AUTOSAR XML (schema 00048)
package /ComponentTypes
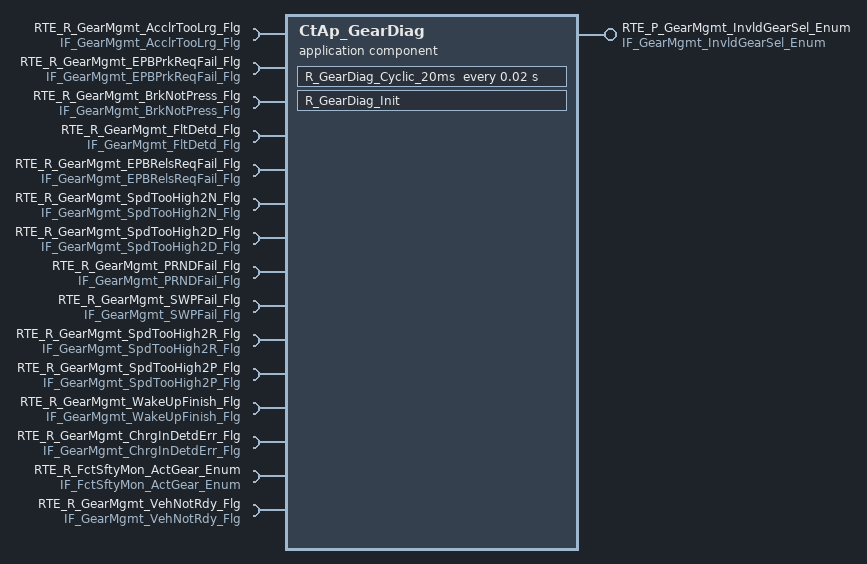
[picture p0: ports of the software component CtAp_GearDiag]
  application sw component type CtAp_GearDiag
    12 x require port:
      RTE_R_GearMgmt_AcclrTooLrg_Flg: nonqueued-receiver-com-spec{data-element=tec_GearMgmt_AcclrTooLrg_Flg, filter=data-filter-type=ALWAYS, init-value=0}, required-interface=IF_GearMgmt_AcclrTooLrg_Flg
      RTE_R_GearMgmt_EPBPrkReqFail_Flg: nonqueued-receiver-com-spec{data-element=tec_GearMgmt_EPBPrkReqFail_Flg, filter=data-filter-type=ALWAYS, init-value=0}, required-interface=IF_GearMgmt_EPBPrkReqFail_Flg
      RTE_R_GearMgmt_BrkNotPress_Flg: nonqueued-receiver-com-spec{data-element=tec_GearMgmt_BrkNotPress_Flg, filter=data-filter-type=ALWAYS, init-value=0}, required-interface=IF_GearMgmt_BrkNotPress_Flg
      RTE_R_GearMgmt_FltDetd_Flg: nonqueued-receiver-com-spec{data-element=tec_GearMgmt_FltDetd_Flg, filter=data-filter-type=ALWAYS, init-value=0}, required-interface=IF_GearMgmt_FltDetd_Flg
      RTE_R_GearMgmt_EPBRelsReqFail_Flg: nonqueued-receiver-com-spec{data-element=tec_GearMgmt_EPBRelsReqFail_Flg, filter=data-filter-type=ALWAYS, init-value=0}, required-interface=IF_GearMgmt_EPBRelsReqFail_Flg
      RTE_R_GearMgmt_SpdTooHigh2N_Flg: nonqueued-receiver-com-spec{data-element=tec_GearMgmt_SpdTooHigh2N_Flg, filter=data-filter-type=ALWAYS, init-value=0}, required-interface=IF_GearMgmt_SpdTooHigh2N_Flg
      RTE_R_GearMgmt_SpdTooHigh2D_Flg: nonqueued-receiver-com-spec{data-element=tec_GearMgmt_SpdTooHigh2D_Flg, filter=data-filter-type=ALWAYS, init-value=0}, required-interface=IF_GearMgmt_SpdTooHigh2D_Flg
      RTE_R_GearMgmt_PRNDFail_Flg: nonqueued-receiver-com-spec{data-element=tec_GearMgmt_PRNDFail_Flg, filter=data-filter-type=ALWAYS, init-value=0}, required-interface=IF_GearMgmt_PRNDFail_Flg
      RTE_R_GearMgmt_SWPFail_Flg: nonqueued-receiver-com-spec{data-element=tec_GearMgmt_SWPFail_Flg, filter=data-filter-type=ALWAYS, init-value=0}, required-interface=IF_GearMgmt_SWPFail_Flg
      RTE_R_GearMgmt_SpdTooHigh2R_Flg: nonqueued-receiver-com-spec{data-element=tec_GearMgmt_SpdTooHigh2R_Flg, filter=data-filter-type=ALWAYS, init-value=0}, required-interface=IF_GearMgmt_SpdTooHigh2R_Flg
      RTE_R_GearMgmt_SpdTooHigh2P_Flg: nonqueued-receiver-com-spec{data-element=tec_GearMgmt_SpdTooHigh2P_Flg, filter=data-filter-type=ALWAYS, init-value=0}, required-interface=IF_GearMgmt_SpdTooHigh2P_Flg
      RTE_R_GearMgmt_WakeUpFinish_Flg: nonqueued-receiver-com-spec{data-element=tec_GearMgmt_WakeUpFinish_Flg, filter=data-filter-type=ALWAYS, init-value=0}, required-interface=IF_GearMgmt_WakeUpFinish_Flg
    provide port RTE_P_GearMgmt_InvldGearSel_Enum: nonqueued-sender-com-spec{data-element=tec_GearMgmt_InvldGearSel_Enum, init-value=0}, provided-interface=IF_GearMgmt_InvldGearSel_Enum
    require port RTE_R_GearMgmt_ChrgInDetdErr_Flg: nonqueued-receiver-com-spec{data-element=tec_GearMgmt_ChrgInDetdErr_Flg, filter=data-filter-type=ALWAYS, init-value=0}, required-interface=IF_GearMgmt_ChrgInDetdErr_Flg
    require port RTE_R_FctSftyMon_ActGear_Enum: nonqueued-receiver-com-spec{data-element=tec_FctSftyMon_ActGear_Enum, filter=data-filter-type=ALWAYS, init-value=0}, required-interface=IF_FctSftyMon_ActGear_Enum
    require port RTE_R_GearMgmt_VehNotRdy_Flg: nonqueued-receiver-com-spec{data-element=tec_GearMgmt_VehNotRdy_Flg, filter=data-filter-type=ALWAYS, init-value=0}, required-interface=IF_GearMgmt_VehNotRdy_Flg
    behavior CtAp_GearDiag_InternalBehavior
      timing event TMT_R_GearDiag_Cyclic_20ms: start-on-event=R_GearDiag_Cyclic_20ms, period=0.02
      init event CtAp_GearDiag_InitEvent: start-on-event=R_GearDiag_Init
      runnable R_GearDiag_Cyclic_20ms
        data-receive-point-by-arguments:
          15 x access:
            REC_RTE_R_GearMgmt_AcclrTooLrg_Flg_tec_GearMgmt_AcclrTooLrg_Flg: accessed-variable=RTE_R_GearMgmt_AcclrTooLrg_Flg.tec_GearMgmt_AcclrTooLrg_Flg
            REC_RTE_R_GearMgmt_BrkNotPress_Flg_tec_GearMgmt_BrkNotPress_Flg: accessed-variable=RTE_R_GearMgmt_BrkNotPress_Flg.tec_GearMgmt_BrkNotPress_Flg
            REC_RTE_R_GearMgmt_EPBPrkReqFail_Flg_tec_GearMgmt_EPBPrkReqFail_Flg: accessed-variable=RTE_R_GearMgmt_EPBPrkReqFail_Flg.tec_GearMgmt_EPBPrkReqFail_Flg
            REC_RTE_R_GearMgmt_EPBRelsReqFail_Flg_tec_GearMgmt_EPBRelsReqFail_Flg: accessed-variable=RTE_R_GearMgmt_EPBRelsReqFail_Flg.tec_GearMgmt_EPBRelsReqFail_Flg
            REC_RTE_R_GearMgmt_FltDetd_Flg_tec_GearMgmt_FltDetd_Flg: accessed-variable=RTE_R_GearMgmt_FltDetd_Flg.tec_GearMgmt_FltDetd_Flg
            REC_RTE_R_GearMgmt_PRNDFail_Flg_tec_GearMgmt_PRNDFail_Flg: accessed-variable=RTE_R_GearMgmt_PRNDFail_Flg.tec_GearMgmt_PRNDFail_Flg
            REC_RTE_R_GearMgmt_SWPFail_Flg_tec_GearMgmt_SWPFail_Flg: accessed-variable=RTE_R_GearMgmt_SWPFail_Flg.tec_GearMgmt_SWPFail_Flg
            REC_RTE_R_GearMgmt_SpdTooHigh2D_Flg_tec_GearMgmt_SpdTooHigh2D_Flg: accessed-variable=RTE_R_GearMgmt_SpdTooHigh2D_Flg.tec_GearMgmt_SpdTooHigh2D_Flg
            REC_RTE_R_GearMgmt_SpdTooHigh2N_Flg_tec_GearMgmt_SpdTooHigh2N_Flg: accessed-variable=RTE_R_GearMgmt_SpdTooHigh2N_Flg.tec_GearMgmt_SpdTooHigh2N_Flg
            REC_RTE_R_GearMgmt_SpdTooHigh2P_Flg_tec_GearMgmt_SpdTooHigh2P_Flg: accessed-variable=RTE_R_GearMgmt_SpdTooHigh2P_Flg.tec_GearMgmt_SpdTooHigh2P_Flg
            REC_RTE_R_GearMgmt_SpdTooHigh2R_Flg_tec_GearMgmt_SpdTooHigh2R_Flg: accessed-variable=RTE_R_GearMgmt_SpdTooHigh2R_Flg.tec_GearMgmt_SpdTooHigh2R_Flg
            REC_RTE_R_GearMgmt_WakeUpFinish_Flg_tec_GearMgmt_WakeUpFinish_Flg: accessed-variable=RTE_R_GearMgmt_WakeUpFinish_Flg.tec_GearMgmt_WakeUpFinish_Flg
            REC_RTE_R_GearMgmt_ChrgInDetdErr_Flg_tec_GearMgmt_ChrgInDetdErr_Flg: accessed-variable=RTE_R_GearMgmt_ChrgInDetdErr_Flg.tec_GearMgmt_ChrgInDetdErr_Flg
            REC_RTE_R_FctSftyMon_ActGear_Enum_tec_FctSftyMon_ActGear_Enum: accessed-variable=RTE_R_FctSftyMon_ActGear_Enum.tec_FctSftyMon_ActGear_Enum
            SEND_RTE_R_GearMgmt_VehNotRdy_Flg_tec_GearMgmt_VehNotRdy_Flg: accessed-variable=RTE_R_GearMgmt_VehNotRdy_Flg.tec_GearMgmt_VehNotRdy_Flg
        data-send-points:
          access SEND_RTE_P_GearMgmt_InvldGearSel_Enum_tec_GearMgmt_InvldGearSel_Enum: accessed-variable=RTE_P_GearMgmt_InvldGearSel_Enum.tec_GearMgmt_InvldGearSel_Enum
      runnable R_GearDiag_Init
  swc implementation CtAp_GearDiag_Implementation: behavior=CtAp_GearDiag_InternalBehavior
